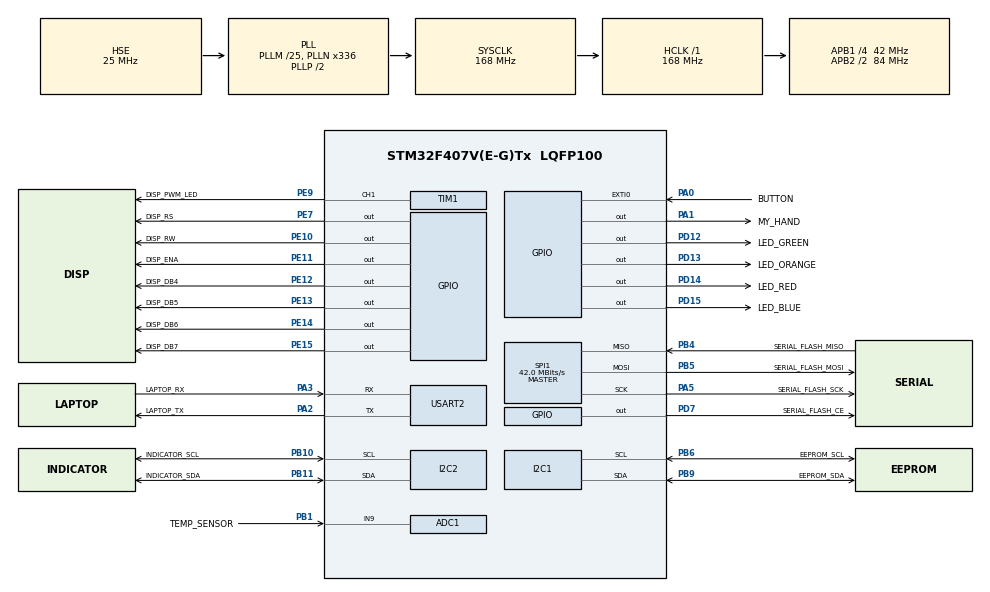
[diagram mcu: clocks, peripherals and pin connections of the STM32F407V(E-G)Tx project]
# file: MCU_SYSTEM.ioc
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ADC1.Channel-0\#ChannelRegularConversion=ADC_CHANNEL_9
ADC1.Channel-1\#ChannelInjectedConversion=ADC_CHANNEL_VREFINT
ADC1.Channel-2\#ChannelInjectedConversion=ADC_CHANNEL_9
ADC1.ExternalTrigInjecConv=ADC_EXTERNALTRIGINJECCONV_T5_TRGO
ADC1.InjNumberOfConversion=2
ADC1.InjectedOffset-1\#ChannelInjectedConversion=0
ADC1.InjectedOffset-2\#ChannelInjectedConversion=0
ADC1.InjectedRank-1\#ChannelInjectedConversion=1
ADC1.InjectedRank-2\#ChannelInjectedConversion=2
ADC1.NbrOfConversionFlag=1
ADC1.Rank-0\#ChannelRegularConversion=1
ADC1.SamplingTime-0\#ChannelRegularConversion=ADC_SAMPLETIME_3CYCLES
ADC1.SamplingTime-1\#ChannelInjectedConversion=ADC_SAMPLETIME_144CYCLES
ADC1.SamplingTime-2\#ChannelInjectedConversion=ADC_SAMPLETIME_144CYCLES
ADC1.ScanConvMode=ENABLE
ADC1.master=1
I2C1.OwnAddress=0x50
Mcu.Family=STM32F4
Mcu.Name=STM32F407V(E-G)Tx
Mcu.Package=LQFP100
NVIC.PriorityGroup=NVIC_PRIORITYGROUP_4
PA0-WKUP.GPIO_Label=BUTTON
PA0-WKUP.Signal=GPXTI0
PA1.GPIO_Label=MY_HAND
PA1.Signal=GPIO_Output
PA13.Mode=Serial_Wire
PA13.Signal=SYS_JTMS-SWDIO
PA14.Mode=Serial_Wire
PA14.Signal=SYS_JTCK-SWCLK
PA2.GPIO_Label=LAPTOP_TX
PA2.Mode=Asynchronous
PA2.Signal=USART2_TX
PA3.GPIO_Label=LAPTOP_RX
PA3.Mode=Asynchronous
PA3.Signal=USART2_RX
PA5.GPIO_Label=SERIAL_FLASH_SCK
PA5.Mode=Full_Duplex_Master
PA5.Signal=SPI1_SCK
PB1.GPIO_Label=TEMP_SENSOR
PB1.Signal=ADCx_IN9
PB10.GPIO_Label=INDICATOR_SCL
PB10.Mode=I2C
PB10.Signal=I2C2_SCL
PB11.GPIO_Label=INDICATOR_SDA
PB11.Mode=I2C
PB11.Signal=I2C2_SDA
PB4.GPIO_Label=SERIAL_FLASH_MISO
PB4.Mode=Full_Duplex_Master
PB4.Signal=SPI1_MISO
PB5.GPIO_Label=SERIAL_FLASH_MOSI
PB5.Mode=Full_Duplex_Master
PB5.Signal=SPI1_MOSI
PB6.GPIO_Label=EEPROM_SCL
PB6.Mode=I2C
PB6.Signal=I2C1_SCL
PB9.GPIO_Label=EEPROM_SDA
PB9.Mode=I2C
PB9.Signal=I2C1_SDA
PD12.GPIO_Label=LED_GREEN
PD12.Signal=GPIO_Output
PD13.GPIO_Label=LED_ORANGE
PD13.Signal=GPIO_Output
PD14.GPIO_Label=LED_RED
PD14.Signal=GPIO_Output
PD15.GPIO_Label=LED_BLUE
PD15.Signal=GPIO_Output
PD7.GPIO_Label=SERIAL_FLASH_CE
PD7.Signal=GPIO_Output
PE10.GPIO_Label=DISP_RW
PE10.GPIO_Speed=GPIO_SPEED_FREQ_VERY_HIGH
PE10.Signal=GPIO_Output
PE11.GPIO_Label=DISP_ENA
PE11.GPIO_Speed=GPIO_SPEED_FREQ_VERY_HIGH
PE11.Signal=GPIO_Output
PE12.GPIO_Label=DISP_DB4
PE12.GPIO_Speed=GPIO_SPEED_FREQ_VERY_HIGH
PE12.Signal=GPIO_Output
PE13.GPIO_Label=DISP_DB5
PE13.GPIO_Speed=GPIO_SPEED_FREQ_VERY_HIGH
PE13.Signal=GPIO_Output
PE14.GPIO_Label=DISP_DB6
PE14.GPIO_Speed=GPIO_SPEED_FREQ_VERY_HIGH
PE14.Signal=GPIO_Output
PE15.GPIO_Label=DISP_DB7
PE15.GPIO_Speed=GPIO_SPEED_FREQ_VERY_HIGH
PE15.Signal=GPIO_Output
PE7.GPIO_Label=DISP_RS
PE7.GPIO_Speed=GPIO_SPEED_FREQ_VERY_HIGH
PE7.Signal=GPIO_Output
PE9.GPIO_Label=DISP_PWM_LED
PE9.GPIO_Speed=GPIO_SPEED_FREQ_VERY_HIGH
PE9.Signal=S_TIM1_CH1
PH0-OSC_IN.Mode=HSE-External-Oscillator
PH0-OSC_IN.Signal=RCC_OSC_IN
PH1-OSC_OUT.Mode=HSE-External-Oscillator
PH1-OSC_OUT.Signal=RCC_OSC_OUT
ProjectManager.HeapSize=0x200
ProjectManager.StackSize=0x400
ProjectManager.TargetToolchain=MDK-ARM V5.32
RCC.48MHZClocksFreq_Value=84000000
RCC.AHBFreq_Value=168000000
RCC.APB1CLKDivider=RCC_HCLK_DIV4
RCC.APB1Freq_Value=42000000
RCC.APB1TimFreq_Value=84000000
RCC.APB2CLKDivider=RCC_HCLK_DIV2
RCC.APB2Freq_Value=84000000
RCC.APB2TimFreq_Value=168000000
RCC.CortexFreq_Value=168000000
RCC.HCLKFreq_Value=168000000
RCC.HSE_VALUE=25000000
RCC.HSI_VALUE=16000000
RCC.LSE_VALUE=32768
RCC.PLLM=25
RCC.PLLN=336
RCC.PLLSourceVirtual=RCC_PLLSOURCE_HSE
RCC.SYSCLKFreq_VALUE=168000000
RCC.SYSCLKSource=RCC_SYSCLKSOURCE_PLLCLK
RCC.VCOOutputFreq_Value=336000000
SH.ADCx_IN9.0=ADC1_IN9,IN9
SH.S_TIM1_CH1.0=TIM1_CH1,PWM Generation1 CH1
SPI1.CalculateBaudRate=42.0 MBits/s
SPI1.Direction=SPI_DIRECTION_2LINES
SPI1.Mode=SPI_MODE_MASTER
SPI1.VirtualType=VM_MASTER
TIM1.Channel-PWM\ Generation1\ CH1=TIM_CHANNEL_1
TIM1.Period=1000-1
TIM1.Prescaler=168-1
TIM5.Period=10000-1
TIM5.Prescaler=16800-1
TIM5.TIM_MasterOutputTrigger=TIM_TRGO_UPDATE
TIM6.Prescaler=84-1
USART2.VirtualMode=VM_ASYNC
VP_ADC1_Vref_Input.Mode=IN-Vrefint
VP_TIM1_VS_ClockSourceINT.Mode=Internal
VP_TIM5_VS_ClockSourceINT.Mode=Internal
VP_TIM6_VS_ClockSourceINT.Mode=Enable_Timer
VP_TIM6_VS_OPM.Mode=OPM_bit
board=custom

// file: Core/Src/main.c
/* USER CODE BEGIN Header */
/**
  ******************************************************************************
  * @file           : main.c
  * @brief          : Main program body
  ******************************************************************************
  * @attention
  *
  * Copyright (c) 2022 STMicroelectronics.
  * All rights reserved.
  *
  * This software is licensed under terms that can be found in the LICENSE file
  * in the root directory of this software component.
  * If no LICENSE file comes with this software, it is provided AS-IS.
  *
  ******************************************************************************
  */
/* USER CODE END Header */
#include "main.h"
#include "adc.h"
#include "i2c.h"
#include "spi.h"
#include "tim.h"
#include "usart.h"
#include "gpio.h"

/* USER CODE BEGIN Includes */
#include <string.h>
#include "inc/ssd1306.h"
/* USER CODE END Includes */

/* USER CODE BEGIN PV */
bool status = false;
/* USER CODE END PV */

void SystemClock_Config(void);

int main(void)
{

  /* MCU Configuration--------------------------------------------------------*/

  /* Reset of all peripherals, Initializes the Flash interface and the Systick. */
  HAL_Init();

  /* Configure the system clock */
  SystemClock_Config();

  /* Initialize all configured peripherals */
  MX_GPIO_Init();
  MX_ADC1_Init();
  MX_I2C1_Init();
  MX_I2C2_Init();
  MX_SPI1_Init();
  MX_TIM1_Init();
  MX_TIM6_Init();
  MX_USART2_UART_Init();
  MX_TIM5_Init();

  /* Infinite loop */
  while (1)
  {

  }
}

void SystemClock_Config(void)
{
  RCC_OscInitTypeDef RCC_OscInitStruct = {0};
  RCC_ClkInitTypeDef RCC_ClkInitStruct = {0};

  /** Configure the main internal regulator output voltage
  */
  __HAL_RCC_PWR_CLK_ENABLE();
  __HAL_PWR_VOLTAGESCALING_CONFIG(PWR_REGULATOR_VOLTAGE_SCALE1);

  /** Initializes the RCC Oscillators according to the specified parameters
  * in the RCC_OscInitTypeDef structure.
  */
  RCC_OscInitStruct.OscillatorType = RCC_OSCILLATORTYPE_HSE;
  RCC_OscInitStruct.HSEState = RCC_HSE_ON;
  RCC_OscInitStruct.PLL.PLLState = RCC_PLL_ON;
  RCC_OscInitStruct.PLL.PLLSource = RCC_PLLSOURCE_HSE;
  RCC_OscInitStruct.PLL.PLLM = 25;
  RCC_OscInitStruct.PLL.PLLN = 336;
  RCC_OscInitStruct.PLL.PLLP = RCC_PLLP_DIV2;
  RCC_OscInitStruct.PLL.PLLQ = 4;
  if (HAL_RCC_OscConfig(&RCC_OscInitStruct) != HAL_OK)
  {
    Error_Handler();
  }

  /** Initializes the CPU, AHB and APB buses clocks
  */
  RCC_ClkInitStruct.ClockType = RCC_CLOCKTYPE_HCLK|RCC_CLOCKTYPE_SYSCLK
                              |RCC_CLOCKTYPE_PCLK1|RCC_CLOCKTYPE_PCLK2;
  RCC_ClkInitStruct.SYSCLKSource = RCC_SYSCLKSOURCE_PLLCLK;
  RCC_ClkInitStruct.AHBCLKDivider = RCC_SYSCLK_DIV1;
  RCC_ClkInitStruct.APB1CLKDivider = RCC_HCLK_DIV4;
  RCC_ClkInitStruct.APB2CLKDivider = RCC_HCLK_DIV2;

  if (HAL_RCC_ClockConfig(&RCC_ClkInitStruct, FLASH_LATENCY_5) != HAL_OK)
  {
    Error_Handler();
  }
}

void Error_Handler(void)
{
  __disable_irq();
  while (1)
  {
  }
}
